AUTOSAR XML (schema 4-0-3)
package /ComponentTypes
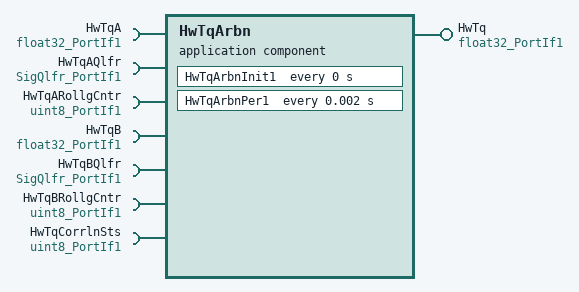
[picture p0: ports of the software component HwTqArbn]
  application sw component type HwTqArbn
    provide port HwTq: nonqueued-sender-com-spec{data-element=Val, init-value=0}, provided-interface=float32_PortIf1
    7 x require port:
      HwTqA: nonqueued-receiver-com-spec{data-element=Val, filter=data-filter-type=ALWAYS, init-value=0}, required-interface=float32_PortIf1
      HwTqAQlfr: nonqueued-receiver-com-spec{data-element=Val, filter=data-filter-type=ALWAYS, init-value=0}, required-interface=SigQlfr_PortIf1
      HwTqARollgCntr: nonqueued-receiver-com-spec{data-element=Val, filter=data-filter-type=ALWAYS, init-value=0}, required-interface=uint8_PortIf1
      HwTqB: nonqueued-receiver-com-spec{data-element=Val, filter=data-filter-type=ALWAYS, init-value=0}, required-interface=float32_PortIf1
      HwTqBQlfr: nonqueued-receiver-com-spec{data-element=Val, filter=data-filter-type=ALWAYS, init-value=0}, required-interface=SigQlfr_PortIf1
      HwTqBRollgCntr: nonqueued-receiver-com-spec{data-element=Val, filter=data-filter-type=ALWAYS, init-value=0}, required-interface=uint8_PortIf1
      HwTqCorrlnSts: nonqueued-receiver-com-spec{data-element=Val, filter=data-filter-type=ALWAYS, init-value=3}, required-interface=uint8_PortIf1
    behavior HwTqArbn_InternalBehavior
      ar-typed-per-instance-memorys:
        6 x data, all with sw-calibration-access=READ-ONLY:
          dHwTqArbnChAAvl: type=boolean
          HwTqARollgCntrPrev: type=uint8
          HwTqAStallCntrPrev: type=uint8
          HwTqBRollgCntrPrev: type=uint8
          HwTqBStallCntrPrev: type=uint8
          HwTqPrevHwTq: type=float32
      timing event HwTqArbn_InitEvent: start-on-event=HwTqArbnInit1, period=0
      timing event TMT_HwTqArbnPer1: start-on-event=HwTqArbnPer1, period=0.002
      runnable HwTqArbnInit1
      runnable HwTqArbnPer1
        data-receive-point-by-arguments:
          7 x access:
            REC_HwTqA_Val: accessed-variable=HwTqA.Val
            REC_HwTqAQlfr_Val: accessed-variable=HwTqAQlfr.Val
            REC_HwTqARollgCntr_Val: accessed-variable=HwTqARollgCntr.Val
            REC_HwTqB_Val: accessed-variable=HwTqB.Val
            REC_HwTqBQlfr_Val: accessed-variable=HwTqBQlfr.Val
            REC_HwTqBRollgCntr_Val: accessed-variable=HwTqBRollgCntr.Val
            REC_HwTqCorrlnSts_Val: accessed-variable=HwTqCorrlnSts.Val
        data-send-points:
          access SEND_HwTq_Val: accessed-variable=HwTq.Val
  swc implementation HwTqArbn_Implementation: behavior=HwTqArbn_InternalBehavior
    code-descriptors:
      code Default: artifact-descriptors=autosar-engineering-object={short-label=Default, category=SWSRC}
